# nrf5002 register map
Vendor: Nordic Semiconductor; Series: nRF50; File version: 1
CPU: CM0 r0p4, little endian, no MPU, no FPU, 2 interrupt priority bits, 32 interrupts
Registers are 32-bit, read-write, reset 0x0 unless marked. A register's access mark holds for its fields unless they carry their own. Offsets are from the block's base; [hi:lo] are bit positions; {n}, {i} and the like mark numbered series; 'fields as' and 'values as' point back to an identical list.

## NVMC — Non Volatile Memory Controller
Base 0x40023000; alternate view of BPROT
0x400 READY ro reset 0x1 — Ready flag
  [0] READY — NVMC is ready or busy
    0=Busy (NVMC is busy (on-going write or erase operation)); 1=Ready (NVMC is ready)
0x408 READYNEXT ro reset 0x1 — Ready flag
  [0] READYNEXT — NVMC can accept a new write operation
    0=Busy (NVMC cannot accept any write operation); 1=Ready (NVMC is ready)
0x40C TESTWORDSTATE ro — Test word status
  [1:0] STATE — State of the least significant bit in the test word
    0=Erased; 1=InvPgm (Inverse programmed); 2=Written0; 3=Written1
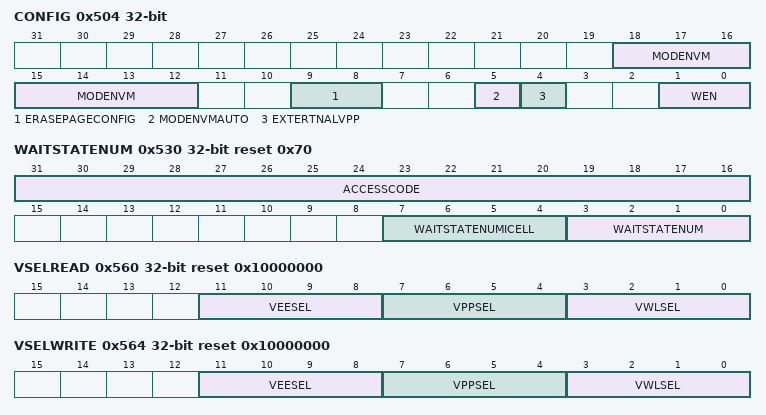
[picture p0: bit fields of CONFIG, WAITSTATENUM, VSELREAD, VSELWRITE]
0x504 CONFIG — Configuration register
  [18:12] MODENVM — MODE signals of the non-volatile memory macro
  [9:8] ERASEPAGECONFIG — Page erase configuration
    0=ReProgramErase (Erase after re-programming the data read and inverse program); 1=InverseProgramErase (Erase after inverse program); 2=Erase (Just erase (no re-program and inverse program))
  [5] MODENVMAUTO — Handling MODE signals of the non-volatile memory macro
    0=Auto (Handled automatically by the non-volatile memory controller); 1=Manual (Set by CONFIG.MODENVM register)
  [4] EXTERTNALVPP — Enable external VPP for write and page erase operations
    0=InternalVpp (Use internal charge pump); 1=ExternalVpp (Use external VPP)
  [1:0] WEN — Program memory access mode. It is strongly recommended to only activate erase and write modes when they are actively used.
    0=Ren (Read only access); 1=Wen (Write enabled); 2=Een (Erase enabled)
0x508 ERASEPAGE wo — Register for erasing a page in code area
  [31:0] ERASEPAGE — Register for starting erase of a page in code area
0x50C ERASEALL wo — Register for erasing all non-volatile user memory
  [0] ERASEALL — Erase all non-volatile memory including UICR registers. The erase must be enabled using CONFIG.WEN before the non-volatile memory can be erased.
    0=NoOperation; 1=Erase (Start chip erase)
0x514 ERASEUICR wo — Register for erasing whole UICR page
  [0] ERASEUICR — Erase UICR page. The erase must be enabled using CONFIG.WEN before the non-volatile memory can be erased.
    0=NoOperation; 1=Erase (Start chip erase)
0x530 WAITSTATENUM reset 0x70 — Register to set the number of wait-state for non-volatile memory access. To update the WAITSTATENUM field, the ACCESSCODE must be correct.
  [31:16] ACCESSCODE — Access code for modifying this register
  [7:4] WAITSTATENUMICELL — Wait-states used while cell current test (set by CONFIG.MODENVM register)
  [3:0] WAITSTATENUM — Non-volatile memory wait-states
0x534 TESTWORD wo — Test the programming state of the least significant bit in a word
  [31:0] ADDRESS — Address of the test word
0x560 VSELREAD reset 0x10000000 — Select output voltage of power generator for read mode
  [11:8] VEESEL — Control the VEESEL signal
  [7:4] VPPSEL — Control the VPPSEL signal
  [3:0] VWLSEL — Control the VWLSEL signal
0x564 VSELWRITE reset 0x10000000 — Select output voltage of power generator for write mode
  fields as VSELREAD
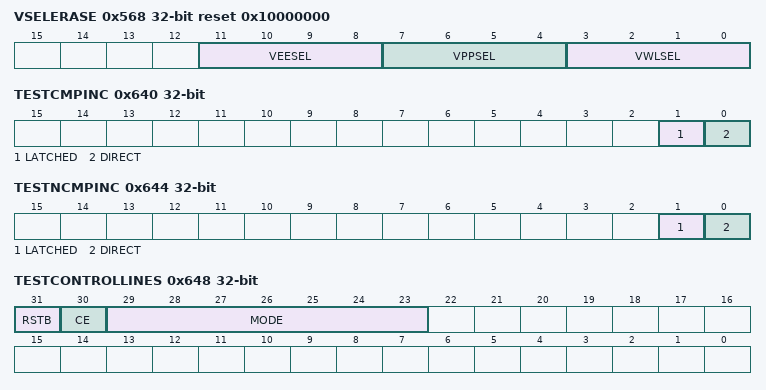
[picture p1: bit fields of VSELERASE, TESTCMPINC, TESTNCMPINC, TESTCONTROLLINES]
0x568 VSELERASE reset 0x10000000 — Select output voltage of power generator for erase mode
  fields as VSELREAD
0x600 TESTMODE — Register for entering test mode. Refer to the MTP IP test documentation for more details.
  [15:0] TESTMODE — Register for entering test mode. Refer to the MTP IP test documentation for more details. This register does not return the same value as written.
    on read: 0=NORMAL (Read: Not in test-mode.); 1=Read: In test-mode 1; 2=Read: In test-mode 2; 4=Read: In test-mode 3 | on write: 0=SetNORMAL (Write: Sets NORMAL mode.); 0xBCDE=SetTESTMODE1 (Write: Sets test-mode 1.); 0xABCD=SetTESTMODE2 (Write: Sets test-mode 2.); 0xCDEF=SetTESTMODE3 (Write: Sets test-mode 3.)
0x610 TESTMASSERASE wo — Self-timed mass-erase operation
  [1:0] TESTMASSERASE
    3=EVERYTHING (Erase everything (all information pages and main block)); 2=NOOPERATION2; 1=NOOPERATION1; 0=NOOPERATION0
{0x620+4i} TESTDATA128[{i}] (i=0..1) — Description collection: Direct MTP test data word n
  [31:0] TESTDATA — Returns data out from MTP when reading. Sets MTP data in when writing.
{0x630+4i} TESTDATA128INC[{i}] (i=0..1) ro — Description collection: Direct MTP test data word n. Post-increments TESTCONTROLADDR
  [31:0] TESTDATA — Returns data out from MTP when reading. Use TESTDATA128[1:0] registers to set the compared data. Post-increments TESTCONTROLADDR. If TESTCONTROLLINES.CE is high, the read starts by pulsing the CE line low for tNRL. If TESTCONTROLLINES.CE is low, CE remains low for the whole access.
0x640 TESTCMPINC ro — Reads and compares last MTP row to TESTDATA128 content. Post-increments TESTCONTROLADDR.
  [1] LATCHED — Reads and compares last MTP row (latched lines) to TESTDATA128 content. Post-increments TESTCONTROLADDR. If TESTCONTROLLINES.CE is high, the read starts by pulsing the CE line low for tNRL. If TESTCONTROLLINES.CE is low, CE remains low for the whole access.
    0=Equal (Latched TESTDATA128 content and MTP row read are equal); 1=NotEqual (Latched TESTDATA128 content and MTP row read are different)
  [0] DIRECT — Reads and compares last MTP row (direct lines) to TESTDATA128 content. Post-increments TESTCONTROLADDR. If TESTCONTROLLINES.CE is high, the read starts by pulsing the CE line low for tNRL. If TESTCONTROLLINES.CE is low, CE remains low for the whole access.
    0=Equal (Direct TESTDATA128 content and MTP row read are equal); 1=NotEqual (Direct TESTDATA128 content and MTP row read are different)
0x644 TESTNCMPINC ro — Reads and compares last MTP row to complement of TESTDATA128 content. Post-increments TESTCONTROLADDR.
  [1] LATCHED — Reads and compares last MTP row (latched lines) to the complement of TESTDATA128 content (all bits inverted). Post-increments TESTCONTROLADDR. If TESTCONTROLLINES.CE is high, the read starts by pulsing the CE line low for tNRL. If TESTCONTROLLINES.CE is low, CE remains low for the whole access.
    0=Complement (Latched TESTDATA128 content and MTP row read are each-other's complement); 1=NotComplement (Latched TESTDATA128 content and MTP row read are not each-other's complement)
  [0] DIRECT — Reads and compares last MTP row (direct lines) to the complement of TESTDATA128 content (all bits inverted). Post-increments TESTCONTROLADDR. If TESTCONTROLLINES.CE is high, the read starts by pulsing the CE line low for tNRL. If TESTCONTROLLINES.CE is low, CE remains low for the whole access.
    0=Complement (Direct TESTDATA128 content and MTP row read are each-other's complement); 1=NotComplement (Direct TESTDATA128 content and MTP row read are not each-other's complement)
0x648 TESTCONTROLLINES — Direct MTP test, control lines. Refer to the MTP IP documentation for more details.
  [31] RSTB — Control the RSTB signal
  [30] CE — Control the CE signal
  [29:23] MODE — Control the MODE signal
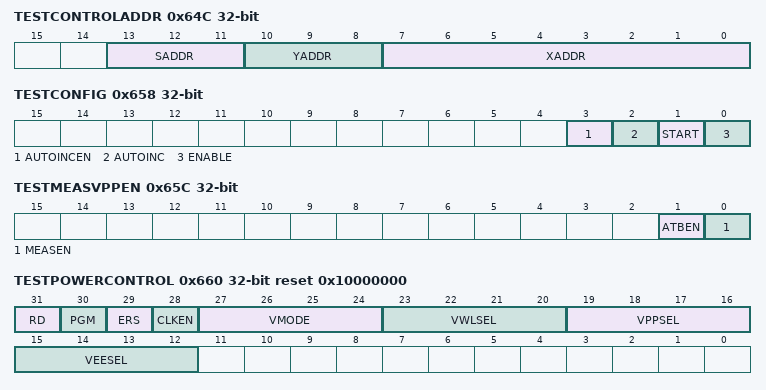
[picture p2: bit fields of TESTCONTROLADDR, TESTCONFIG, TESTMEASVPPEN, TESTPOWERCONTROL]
0x64C TESTCONTROLADDR — Direct MTP test control, address lines
  [13:11] SADDR — Control the SADDR signal
  [10:8] YADDR — Control the YADDR signal
  [7:0] XADDR — Control the X address signal
0x650 TESTCOUNTERRELOAD — Counter reload value, used when counting from CE rising edge to latching of data
  [11:0] RELOAD — Counter reload value, in MCU bus cycles, used when counting from CE rising edge to latching of data. Value of 0 has no effect (counter will not latch)
0x654 TESTCOUNTERRUNNING ro — Returns the state (counting or not) of the counter
  [0] RUNNING — Returns the state of the counter
    0=NotRunning (Counter is not running); 1=Running (Counter is running)
0x658 TESTCONFIG — Mode of operation of the counter
  [3] AUTOINCEN — Disables the address auto-increment or -decrement
    1=Disable (Address auto-incrementing/decrementing is disabled); 0=Enable (Address auto-incrementing/decrementing is enabled)
  [2] AUTOINC — Controls the address auto-increment or -decrement
    0=Increment (Address is auto-incrementing); 1=Decrement (Address is auto-decrementing)
  [1] START — Defines the starting point of the counter
    0=CE (Counter starts on CE rising edge); 1=None
  [0] ENABLE — Returns the state of the counter
    0=Disabled (Counter is disabled); 1=Enabled (Counter is enabled)
0x65C TESTMEASVPPEN — Controls analog signals for MTP measurements
  [1] ATBEN — Enable the analog test bus (ATB) connecting VEEE and VWLE from MTP. The VPP has dedicated pin called DECP.
    0=Disabled (ATB disabled); 1=Enabled (ATB enabled)
  [0] MEASEN — Analog enable for Cell Current Measurement Port. Needs to be set when measuring MEAS on P0.00.
    0=Disabled (MEAS pad disabled); 1=Enabled (MEAS pad enabled)
0x660 TESTPOWERCONTROL reset 0x10000000 — Direct test, control lines to the MTP power generator module. Refer to the MTP IP documentation for more details.
  [31] RD — Control the RD (read enable) signal
  [30] PGM — Control the PGM (program enable) signal
  [29] ERS — Control the ERS (erase enable) signal
  [28] CLKEN — Enable clock from PCGC to the CLK signal
  [27:24] VMODE — Control the VMODE signal
  [23:20] VWLSEL — Control the VWLSEL signal
  [19:16] VPPSEL — Control the VPPSEL signal
  [15:12] VEESEL — Control the VEESEL signal
0x700 FORCEONNVM — Force on NVM supply
  [0] FORCEONNVM
    0=Do not force on NVM supply; 1=Force on NVM supply
0x728 FORCEOFFNVM — Force off NVM supply
  [31:0] FORCEOFFNVM
    on read: 0=NotForcedOff (Read: NVM supply not forced off); 1=ForcedOff (Read: NVM supply force off) | on write: 0=DisableForceOff (Write: Do not force off NVM supply); 0xACCE5500=EnableForceOff (Write: Force off NVM supply)
